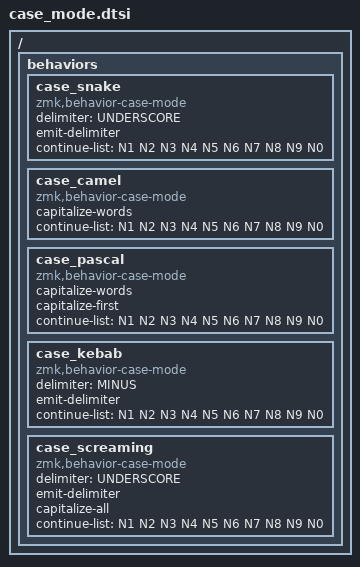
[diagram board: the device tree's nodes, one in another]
/*
 * Copyright (c) 2024 The ZMK Contributors
 *
 * SPDX-License-Identifier: MIT
 */

#include <dt-bindings/zmk/keys.h>

/ {
    behaviors {
        /omit-if-no-ref/ case_snake: case_snake {
            compatible = "zmk,behavior-case-mode";
            #binding-cells = <0>;
            delimiter = <UNDERSCORE>;
            emit-delimiter;
            continue-list = <N1 N2 N3 N4 N5 N6 N7 N8 N9 N0>;
        };

        /omit-if-no-ref/ case_camel: case_camel {
            compatible = "zmk,behavior-case-mode";
            #binding-cells = <0>;
            capitalize-words;
            continue-list = <N1 N2 N3 N4 N5 N6 N7 N8 N9 N0>;
        };

        /omit-if-no-ref/ case_pascal: case_pascal {
            compatible = "zmk,behavior-case-mode";
            #binding-cells = <0>;
            capitalize-words;
            capitalize-first;
            continue-list = <N1 N2 N3 N4 N5 N6 N7 N8 N9 N0>;
        };

        /omit-if-no-ref/ case_kebab: case_kebab {
            compatible = "zmk,behavior-case-mode";
            #binding-cells = <0>;
            delimiter = <MINUS>;
            emit-delimiter;
            continue-list = <N1 N2 N3 N4 N5 N6 N7 N8 N9 N0>;
        };

        /omit-if-no-ref/ case_screaming: case_screaming {
            compatible = "zmk,behavior-case-mode";
            #binding-cells = <0>;
            delimiter = <UNDERSCORE>;
            emit-delimiter;
            capitalize-all;
            continue-list = <N1 N2 N3 N4 N5 N6 N7 N8 N9 N0>;
        };
    };
};
